# PIC32MZ1025DAH169 register map
Vendor: Microchip
Registers are 32-bit, read-write, reset 0x0 unless marked. A register's access mark holds for its fields unless they carry their own. Addresses are absolute, and some are shared; only a register's first bit layout is shown; [hi:lo] are bit positions; {n}, {i} and the like mark numbered series; 'fields as' and 'values as' point back to an identical list.

## CONFIG — Configuration words, addresses in PhysicalSpace
0x1FC0FF3C ADEVCFG4 reset 0xFFFFFFFF
  [28:24] SWDTPS — Sleep Mode Watchdog Timer Postscaler
    0=SPS1 (1:1); 1=SPS2 (1:2); 2=SPS4 (1:4); 3=SPS8 (1:8); 4=SPS16 (1:16); 5=SPS32 (1:32); 6=SPS64 (1:64); 7=SPS128 (1:128); 8=SPS256 (1:256); 9=SPS512 (1:512); 10=SPS1024 (1:1024); 11=SPS2048 (1:2048); 12=SPS4096 (1:4096); 13=SPS8192 (1:8192); 14=SPS16384 (1:16384); 15=SPS32768 (1:32768); 0b1x000=SPS65536 (1:65536); 0b1x001=SPS131072 (1:131072); 0b1x010=SPS262144 (1:262144); 0b1x011=SPS524288 (1:524288); 0b1x1xx=SPS1048576 (1:1048576)
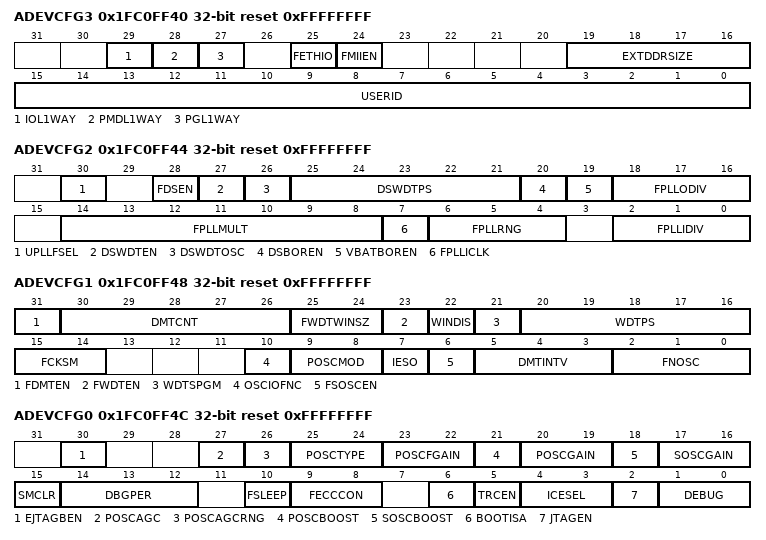
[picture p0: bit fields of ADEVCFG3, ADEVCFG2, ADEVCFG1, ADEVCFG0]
0x1FC0FF40 ADEVCFG3 reset 0xFFFFFFFF
  [29] IOL1WAY — Peripheral Pin Select Configuration
    1=ON (Allow only one reconfiguration); 0=OFF (Allow multiple reconfigurations)
  [28] PMDL1WAY — Peripheral Module Disable Configuration
    values as IOL1WAY
  [27] PGL1WAY — Permission Group Lock One Way Configuration
    values as IOL1WAY
  [25] FETHIO — Ethernet I/O Pin Select
    0=OFF (Alternate Ethernet I/O); 1=ON (Default Ethernet I/O)
  [24] FMIIEN — Ethernet RMII/MII Enable
    0=OFF (RMII Enabled); 1=ON (MII Enabled)
  [19:16] EXTDDRSIZE — External DDR2 SDRAM Memory Size
    0=DDR_SIZE_1MB (External DDR2 Size is 1 MB); 1=DDR_SIZE_2MB (External DDR2 Size is 2 MB); 2=DDR_SIZE_4MB (External DDR2 Size is 4 MB); 3=DDR_SIZE_8MB (External DDR2 Size is 8 MB); 4=DDR_SIZE_16MB (External DDR2 Size is 16 MB); 5=DDR_SIZE_32MB (External DDR2 Size is 32 MB); 6=DDR_SIZE_64MB (External DDR2 Size is 64 MB); 15=DDR_SIZE_128MB (External DDR2 Size is 128 MB)
  [15:0] USERID
0x1FC0FF44 ADEVCFG2 reset 0xFFFFFFFF
  [30] UPLLFSEL — USB PLL Input Frequency Selection
    1=FREQ_24MHZ (USB PLL input is 24 MHz); 0=FREQ_12MHZ (USB PLL input is 12 MHz)
  [28] FDSEN — Deep Sleep Enable
    0=OFF (Disable DSEN bit in DSCON); 1=ON (Enable DSEN bit in DSCON)
  [27] DSWDTEN — Deep Sleep Watchdog Timer Enable
    0=OFF (Disable DSWDT during Deep Sleep Mode); 1=ON (Enable DSWDT during Deep Sleep Mode)
  [26] DSWDTOSC — Deep Sleep WDT Reference Clock Selection
    0=SOSC (Select SOSC as DSWDT Reference Clock); 1=LPRC (Select LPRC as DSWDT Reference clock)
  [25:21] DSWDTPS — Deep Sleep Watchdog Timer Postscaler
    {v}=DSPS{v+1} (1:2^{v+5}) (v=0..31)
  [20] DSBOREN — Deep Sleep BOR Enable
    0=OFF (Disable ZPBOR during Deep Sleep Mode); 1=ON (Enable ZPBOR during Deep Sleep Mode)
  [19] VBATBOREN — VBAT BOR Enable
    0=OFF (Disable ZPBOR during VBAT Mode); 1=ON (Enable ZPBOR during VBAT Mode)
  [18:16] FPLLODIV — System PLL Output Clock Divider
    1=DIV_2 (2x Divider); 2=DIV_4 (4x Divider); 3=DIV_8 (8x Divider); 4=DIV_16 (16x Divider); 7=DIV_32 (32x Divider)
  [14:8] FPLLMULT — System PLL Multiplier
    {v}=MUL_{v+1} (PLL Multiply by {v+1}) (v=0..127)
  [7] FPLLICLK — System PLL Input Clock Selection
    1=PLL_FRC (FRC is input to the System PLL); 0=PLL_POSC (POSC is input to the System PLL)
  [6:4] FPLLRNG — System PLL Input Range
    0=RANGE_BYPASS (Bypass); 1=RANGE_5_10_MHZ (5-10 MHz Input); 2=RANGE_8_16_MHZ (8-16 MHz Input); 3=RANGE_13_26_MHZ (13-26 MHz Input); 4=RANGE_21_42_MHZ (21-42 MHz Input); 5=RANGE_34_68_MHZ (34-68 MHz Input)
  [2:0] FPLLIDIV — System PLL Input Divider
    {v}=DIV_{v+1} ({v+1}x Divider) (v=0..7)
0x1FC0FF48 ADEVCFG1 reset 0xFFFFFFFF
  [31] FDMTEN — Deadman Timer Enable
    1=ON (Deadman Timer is enabled); 0=OFF (Deadman Timer is disabled)
  [30:26] DMTCNT — Deadman Timer Count Selection
    0=DMT8 (2^8 (256)); 1=DMT9 (2^9 (512)); 2=DMT10 (2^10 (1024)); 3=DMT11 (2^11 (2048)); 4=DMT12 (2^12 (4096)); 5=DMT13 (2^13 (8192)); 6=DMT14 (2^14 (16384)); 7=DMT15 (2^15 (32768)); 8=DMT16 (2^16 (65536)); 9=DMT17 (2^17 (131072)); 10=DMT18 (2^18 (262144)); 11=DMT19 (2^19 (524288)); 12=DMT20 (2^20 (1048576)); 13=DMT21 (2^21 (2097152)); 14=DMT22 (2^22 (4194304)); 15=DMT23 (2^23 (8388608)); 16=DMT24 (2^24 (16777216)); 17=DMT25 (2^25 (33554432)); 18=DMT26 (2^26 (67108864)); 19=DMT27 (2^27 (134217728)); 20=DMT28 (2^28 (268435456)); 21=DMT29 (2^29 (536870912)); 22=DMT30 (2^30 (1073741824)); 23=DMT31 (2^31 (2147483648))
  [25:24] FWDTWINSZ — Watchdog Timer Window Size
    3=WINSZ_25 (Window size is 25%); 2=WINSZ_37 (Window size is 37.5%); 1=WINSZ_50 (Window size is 50%); 0=WINSZ_75 (Window size is 75%)
  [23] FWDTEN — Watchdog Timer Enable
    0=OFF (WDT Disabled); 1=ON (WDT Enabled)
  [22] WINDIS — Watchdog Timer Window Mode
    1=NORMAL (Watchdog Timer is in non-Window mode); 0=WINDOW (Watchdog Timer is in Window mode)
  [21] WDTSPGM — Watchdog Timer Stop During Flash Programming
    0=RUN (WDT runs during Flash programming); 1=STOP (WDT stops during Flash programming)
  [20:16] WDTPS — Watchdog Timer Postscaler
    0=PS1 (1:1); 1=PS2 (1:2); 2=PS4 (1:4); 3=PS8 (1:8); 4=PS16 (1:16); 5=PS32 (1:32); 6=PS64 (1:64); 7=PS128 (1:128); 8=PS256 (1:256); 9=PS512 (1:512); 10=PS1024 (1:1024); 11=PS2048 (1:2048); 12=PS4096 (1:4096); 13=PS8192 (1:8192); 14=PS16384 (1:16384); 15=PS32768 (1:32768); 0b1x000=PS65536 (1:65536); 0b1x001=PS131072 (1:131072); 0b1x010=PS262144 (1:262144); 0b1x011=PS524288 (1:524288); 0b1x1xx=PS1048576 (1:1048576)
  [15:14] FCKSM — Clock Switching and Monitor Selection
    0=CSDCMD (Clock Switch Disabled, FSCM Disabled); 1=CSECMD (Clock Switch Enabled, FSCM Disabled); 2=CSDCME (Clock Switch Disabled, FSCM Enabled); 3=CSECME (Clock Switch Enabled, FSCM Enabled)
  [10] OSCIOFNC — CLKO Output Signal Active on the OSCO Pin
    1=OFF (Disabled); 0=ON (Enabled)
  [9:8] POSCMOD — Primary Oscillator Configuration
    0=EC (External clock mode); 2=HS (HS osc mode); 3=OFF (Primary osc disabled)
  [7] IESO — Internal/External Switch Over
    0=OFF (Disabled); 1=ON (Enabled)
  [6] FSOSCEN — Secondary Oscillator Enable
    0=OFF (Disable Secondary Oscillator); 1=ON (Enable Secondary Oscillator)
  [5:3] DMTINTV — DMT Count Window Interval
    0=WIN_0 (Window/Interval value is zero); 1=WIN_1_2 (Window/Interval value is 1/2 counter value); 2=WIN_3_4 (Window/Interval value is 3/4 counter value); 3=WIN_7_8 (Window/Interval value is 7/8 counter value); 4=WIN_15_16 (Window/Interval value is 15/16 counter value); 5=WIN_31_32 (Window/Interval value is 31/32 counter value); 6=WIN_63_64 (Window/Interval value is 63/64 counter value); 7=WIN_127_128 (Window/Interval value is 127/128 counter value)
  [2:0] FNOSC — Oscillator Selection Bits
    7=FRCDIV (Fast RC Osc w/Div-by-N (FRCDIV)); 1=SPLL (System PLL); 2=POSC (Primary Osc (HS,EC)); 4=SOSC (Low Power Secondary Osc (SOSC)); 5=LPRC (Low Power RC Osc (LPRC))
0x1FC0FF4C ADEVCFG0 reset 0xFFFFFFFF
  [30] EJTAGBEN — EJTAG Boot Enable
    0=REDUCED (Reduced EJTAG functionality); 1=NORMAL (Normal EJTAG functionality)
  [27] POSCAGC — Primary Oscillator Auto Gain Control bit
    1=ON (POSC Auto Gain Control Enabled); 0=OFF (POSC Auto Gain Control Disabled/Manual Gain Control Enabled)
  [26] POSCAGCRNG — Primary Crystal Oscillator AGC Lock Range bit
    1=RANGE_1X; 0=RANGE_5X
  [25:24] POSCTYPE — Primary Oscillator Type bits
    3=CRYSTAL_12MHZ (12 MHz Crystal used as Primary Oscillator); 2=CRYSTAL_24MHZ (24 MHz Crystal used as Primary Oscillator); 1=RESONATOR (Resonator used as Primary Oscillator); 0=CRYSTAL_8MHZ (8 MHz Crystal used as Primary Oscillator)
  [23:22] POSCFGAIN — Primary Crystal Oscillator Final Gain Control
    {v}=GAIN_G{v} (Gain is G{v}) (v=0..3)
  [21] POSCBOOST — Primary Oscillator Boost Kick Start Enable bit
    1=ON (Boost the kick start of the oscillator); 0=OFF (Normal start of the oscillator)
  [20:19] POSCGAIN — Primary Oscillator Gain Control bits
    3=GAIN_2X (2x gain setting); 2=GAIN_1_5X (1.5x gain setting); 0=GAIN_0_5X (0.5x gain setting); 1=GAIN_1X (1x gain setting); 3=GAIN_LEVEL_3 (Gain level 3 (Highest)); 2=GAIN_LEVEL_2; 1=GAIN_LEVEL_1; 0=GAIN_LEVEL_0 (Gain level 0 (Lowest))
  [18] SOSCBOOST — Secondary Oscillator Boost Kick Start Enable bit
    values as POSCBOOST
  [17:16] SOSCGAIN — Secondary Oscillator Gain Control bits
    values as POSCGAIN
  [15] SMCLR — Soft Master Clear Enable
    0=MCLR_POR (MCLR pin generates an emulated POR Reset); 1=MCLR_NORM (MCLR pin generates a normal system Reset)
  [14:12] DBGPER — Debug Mode CPU Access Permission
    4=ALLOW_PG2 (Allow CPU access to Permission Group 2 permission regions); 2=ALLOW_PG1 (Allow CPU access to Permission Group 1 permission regions); 1=ALLOW_PG0 (Allow CPU access to Permission Group 0 permission regions); 3=PG_1_0 (PG0: Allow PG1: Allow PG2: Deny); 5=PG_2_0 (PG0: Allow PG1: Deny PG2: Allow); 6=PG_2_1 (PG0: Deny PG1: Allow PG2: Allow); 7=PG_ALL (Allow CPU access to all permission regions); 0=PG_NONE (Deny CPU access to all permission regions)
  [10] FSLEEP — Flash Sleep Mode
    0=VREGS (Flash power down is controlled by the VREGS bit); 1=OFF (Flash is powered down when the device is in Sleep mode)
  [9:8] FECCCON — Dynamic Flash ECC Configuration
    0=ON (Flash ECC is enabled (ECCCON bits are locked)); 1=DYNAMIC (Dynamic Flash ECC is enabled (ECCCON bits are locked)); 2=OFF_LOCKED (ECC and Dynamic ECC are disabled (ECCCON bits are locked)); 3=OFF_UNLOCKED (ECC and Dynamic ECC are disabled (ECCCON bits are writable))
  [6] BOOTISA — Boot ISA Selection
    1=MIPS32 (Boot code and Exception code is MIPS32); 0=MICROMIPS (Boot code and Exception code is microMIPS)
  [5] TRCEN — Trace Enable
    1=ON (Trace features in the CPU are enabled); 0=OFF (Trace features in the CPU are disabled)
  [4:3] ICESEL — ICE/ICD Comm Channel Select
    3=ICS_PGx1 (Communicate on PGEC1/PGED1); 2=ICS_PGx2 (Communicate on PGEC2/PGED2)
  [2] JTAGEN — JTAG Enable
    1=ON (JTAG Port Enabled); 0=OFF (JTAG Disabled)
  [1:0] DEBUG — Background Debugger Enable
    0=ON (Debugger is enabled); 3=OFF (Debugger is disabled)
0x1FC0FF50 ADEVCP3 access not given reset 0xFFFFFFFF
0x1FC0FF54 ADEVCP2 access not given reset 0xFFFFFFFF
0x1FC0FF58 ADEVCP1 access not given reset 0xFFFFFFFF
0x1FC0FF5C ADEVCP0 reset 0xFFFFFFFF
  [28] CP — Code Protect
    0=ON (Protection Enabled); 1=OFF (Protection Disabled)
0x1FC0FF60 ADEVSIGN3 access not given reset 0xFFFFFFFF
0x1FC0FF64 ADEVSIGN2 access not given reset 0xFFFFFFFF
0x1FC0FF68 ADEVSIGN1 access not given reset 0xFFFFFFFF
0x1FC0FF6C ADEVSIGN0 access not given reset 0x7FFFFFFF
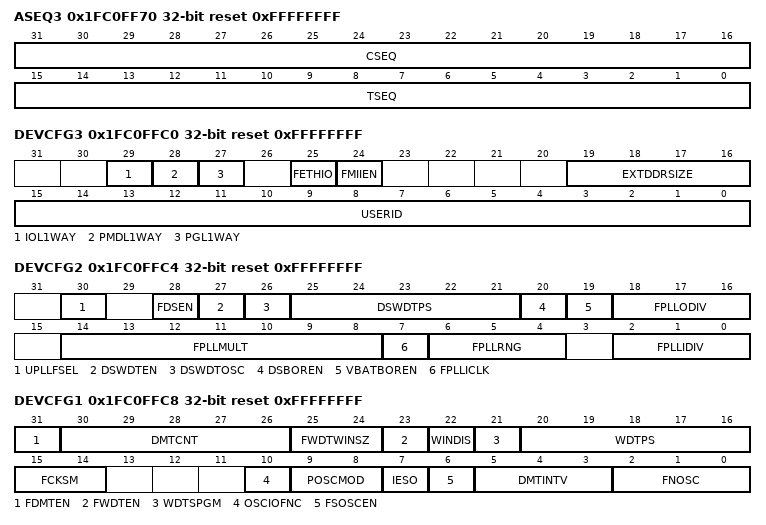
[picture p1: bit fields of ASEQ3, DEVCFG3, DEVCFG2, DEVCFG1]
0x1FC0FF70 ASEQ3 reset 0xFFFFFFFF
  [31:16] CSEQ — Boot Flash Complement Sequence Number
  [15:0] TSEQ — Boot Flash True Sequence Number
0x1FC0FF74 ASEQ2 access not given reset 0xFFFFFFFF
0x1FC0FF78 ASEQ1 access not given reset 0xFFFFFFFF
0x1FC0FF7C ASEQ0 access not given reset 0xFFFFFFFF
0x1FC0FFBC DEVCFG4 reset 0xFFFFFFFF
  fields as ADEVCFG4
0x1FC0FFC0 DEVCFG3 reset 0xFFFFFFFF
  fields as ADEVCFG3
0x1FC0FFC4 DEVCFG2 reset 0xFFFFFFFF
  fields as ADEVCFG2
0x1FC0FFC8 DEVCFG1 reset 0xFFFFFFFF
  fields as ADEVCFG1
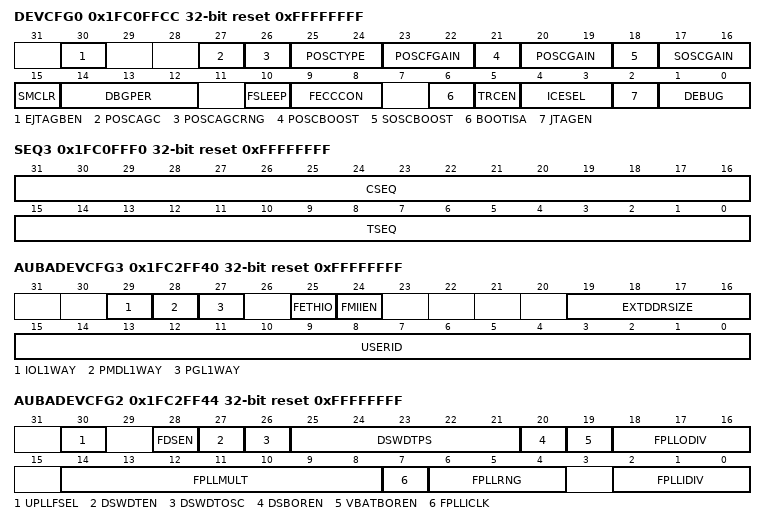
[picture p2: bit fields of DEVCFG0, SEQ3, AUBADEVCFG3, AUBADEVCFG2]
0x1FC0FFCC DEVCFG0 reset 0xFFFFFFFF
  fields as ADEVCFG0
0x1FC0FFD0 DEVCP3 access not given reset 0xFFFFFFFF
0x1FC0FFD4 DEVCP2 access not given reset 0xFFFFFFFF
0x1FC0FFD8 DEVCP1 access not given reset 0xFFFFFFFF
0x1FC0FFDC DEVCP0 reset 0xFFFFFFFF
  fields as ADEVCP0
0x1FC0FFE0 DEVSIGN3 access not given reset 0xFFFFFFFF
0x1FC0FFE4 DEVSIGN2 access not given reset 0xFFFFFFFF
0x1FC0FFE8 DEVSIGN1 access not given reset 0xFFFFFFFF
0x1FC0FFEC DEVSIGN0 access not given reset 0x7FFFFFFF
0x1FC0FFF0 SEQ3 reset 0xFFFFFFFF
  fields as ASEQ3
0x1FC0FFF4 SEQ2 access not given reset 0xFFFFFFFF
0x1FC0FFF8 SEQ1 access not given reset 0xFFFFFFFF
0x1FC0FFFC SEQ0 access not given reset 0xFFFFFFFF
0x1FC2FF3C AUBADEVCFG4 reset 0xFFFFFFFF
  fields as ADEVCFG4
0x1FC2FF40 AUBADEVCFG3 reset 0xFFFFFFFF
  fields as ADEVCFG3
0x1FC2FF44 AUBADEVCFG2 reset 0xFFFFFFFF
  fields as ADEVCFG2
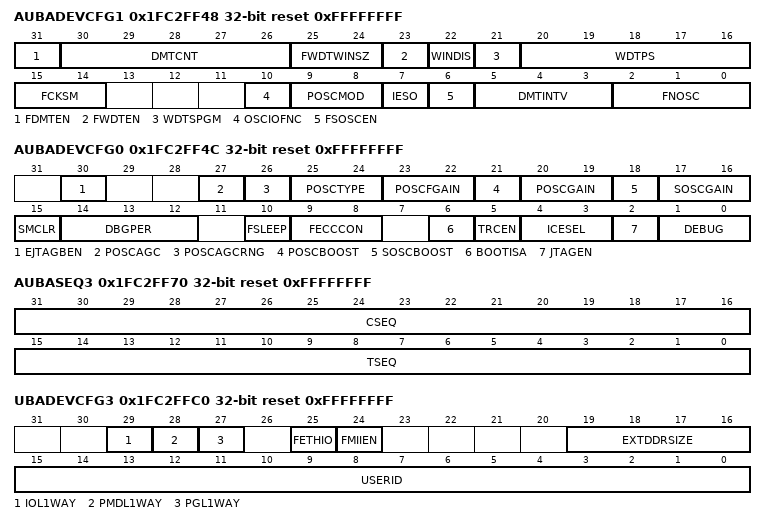
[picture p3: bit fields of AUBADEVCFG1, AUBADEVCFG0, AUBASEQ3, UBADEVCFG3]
0x1FC2FF48 AUBADEVCFG1 reset 0xFFFFFFFF
  fields as ADEVCFG1
0x1FC2FF4C AUBADEVCFG0 reset 0xFFFFFFFF
  fields as ADEVCFG0
0x1FC2FF50 AUBADEVCP3 access not given reset 0xFFFFFFFF
0x1FC2FF54 AUBADEVCP2 access not given reset 0xFFFFFFFF
0x1FC2FF58 AUBADEVCP1 access not given reset 0xFFFFFFFF
0x1FC2FF5C AUBADEVCP0 reset 0xFFFFFFFF
  fields as ADEVCP0
0x1FC2FF60 AUBADEVSIGN3 access not given reset 0xFFFFFFFF
0x1FC2FF64 AUBADEVSIGN2 access not given reset 0xFFFFFFFF
0x1FC2FF68 AUBADEVSIGN1 access not given reset 0xFFFFFFFF
0x1FC2FF6C AUBADEVSIGN0 access not given reset 0x7FFFFFFF
0x1FC2FF70 AUBASEQ3 reset 0xFFFFFFFF
  fields as ASEQ3
0x1FC2FF74 AUBASEQ2 access not given reset 0xFFFFFFFF
0x1FC2FF78 AUBASEQ1 access not given reset 0xFFFFFFFF
0x1FC2FF7C AUBASEQ0 access not given reset 0xFFFFFFFF
0x1FC2FFBC UBADEVCFG4 reset 0xFFFFFFFF
  fields as ADEVCFG4
0x1FC2FFC0 UBADEVCFG3 reset 0xFFFFFFFF
  fields as ADEVCFG3
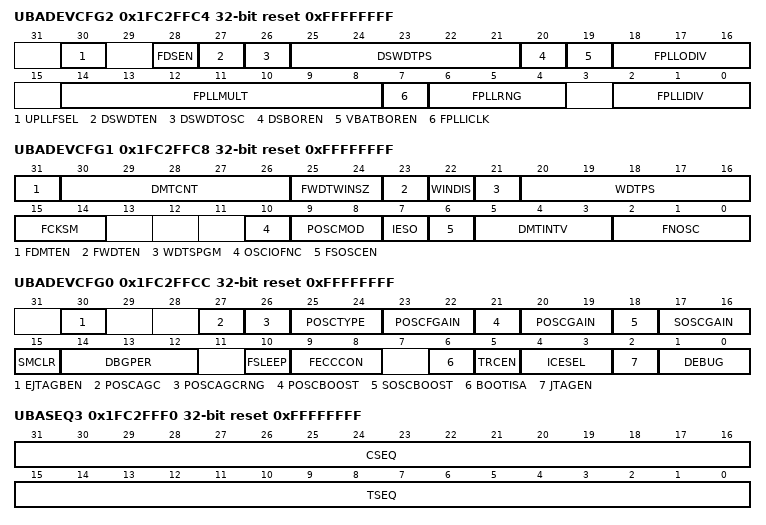
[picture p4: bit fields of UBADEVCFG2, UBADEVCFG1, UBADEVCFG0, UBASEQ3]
0x1FC2FFC4 UBADEVCFG2 reset 0xFFFFFFFF
  fields as ADEVCFG2
0x1FC2FFC8 UBADEVCFG1 reset 0xFFFFFFFF
  fields as ADEVCFG1
0x1FC2FFCC UBADEVCFG0 reset 0xFFFFFFFF
  fields as ADEVCFG0
0x1FC2FFD0 UBADEVCP3 access not given reset 0xFFFFFFFF
0x1FC2FFD4 UBADEVCP2 access not given reset 0xFFFFFFFF
0x1FC2FFD8 UBADEVCP1 access not given reset 0xFFFFFFFF
0x1FC2FFDC UBADEVCP0 reset 0xFFFFFFFF
  fields as ADEVCP0
0x1FC2FFE0 UBADEVSIGN3 access not given reset 0xFFFFFFFF
0x1FC2FFE4 UBADEVSIGN2 access not given reset 0xFFFFFFFF
0x1FC2FFE8 UBADEVSIGN1 access not given reset 0xFFFFFFFF
0x1FC2FFEC UBADEVSIGN0 access not given reset 0x7FFFFFFF
0x1FC2FFF0 UBASEQ3 reset 0xFFFFFFFF
  fields as ASEQ3
0x1FC2FFF4 UBASEQ2 access not given reset 0xFFFFFFFF
0x1FC2FFF8 UBASEQ1 access not given reset 0xFFFFFFFF
0x1FC2FFFC UBASEQ0 access not given reset 0xFFFFFFFF
0x1FC4FF3C ABF1DEVCFG4 reset 0xFFFFFFFF
  fields as ADEVCFG4
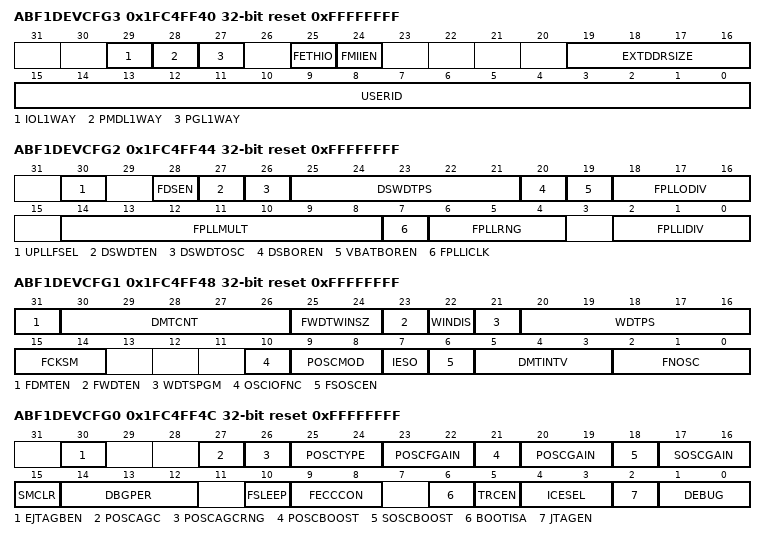
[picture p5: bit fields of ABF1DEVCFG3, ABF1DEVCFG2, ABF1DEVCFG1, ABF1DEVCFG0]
0x1FC4FF40 ABF1DEVCFG3 reset 0xFFFFFFFF
  fields as ADEVCFG3
0x1FC4FF44 ABF1DEVCFG2 reset 0xFFFFFFFF
  fields as ADEVCFG2
0x1FC4FF48 ABF1DEVCFG1 reset 0xFFFFFFFF
  fields as ADEVCFG1
0x1FC4FF4C ABF1DEVCFG0 reset 0xFFFFFFFF
  fields as ADEVCFG0
0x1FC4FF50 ABF1DEVCP3 access not given reset 0xFFFFFFFF
0x1FC4FF54 ABF1DEVCP2 access not given reset 0xFFFFFFFF
0x1FC4FF58 ABF1DEVCP1 access not given reset 0xFFFFFFFF
0x1FC4FF5C ABF1DEVCP0 reset 0xFFFFFFFF
  fields as ADEVCP0
0x1FC4FF60 ABF1DEVSIGN3 access not given reset 0xFFFFFFFF
0x1FC4FF64 ABF1DEVSIGN2 access not given reset 0xFFFFFFFF
0x1FC4FF68 ABF1DEVSIGN1 access not given reset 0xFFFFFFFF
0x1FC4FF6C ABF1DEVSIGN0 access not given reset 0x7FFFFFFF
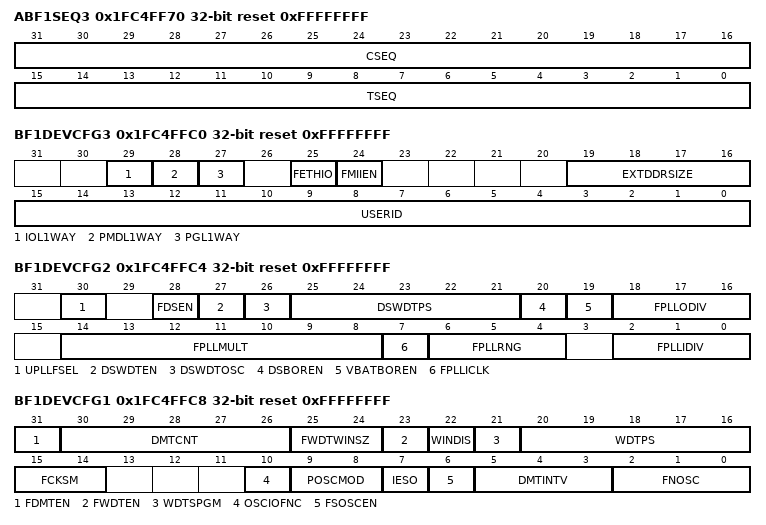
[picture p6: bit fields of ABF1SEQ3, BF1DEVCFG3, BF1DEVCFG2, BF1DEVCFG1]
0x1FC4FF70 ABF1SEQ3 reset 0xFFFFFFFF
  fields as ASEQ3
0x1FC4FF74 ABF1SEQ2 access not given reset 0xFFFFFFFF
0x1FC4FF78 ABF1SEQ1 access not given reset 0xFFFFFFFF
0x1FC4FF7C ABF1SEQ0 access not given reset 0xFFFFFFFF
0x1FC4FFBC BF1DEVCFG4 reset 0xFFFFFFFF
  fields as ADEVCFG4
0x1FC4FFC0 BF1DEVCFG3 reset 0xFFFFFFFF
  fields as ADEVCFG3
0x1FC4FFC4 BF1DEVCFG2 reset 0xFFFFFFFF
  fields as ADEVCFG2
0x1FC4FFC8 BF1DEVCFG1 reset 0xFFFFFFFF
  fields as ADEVCFG1
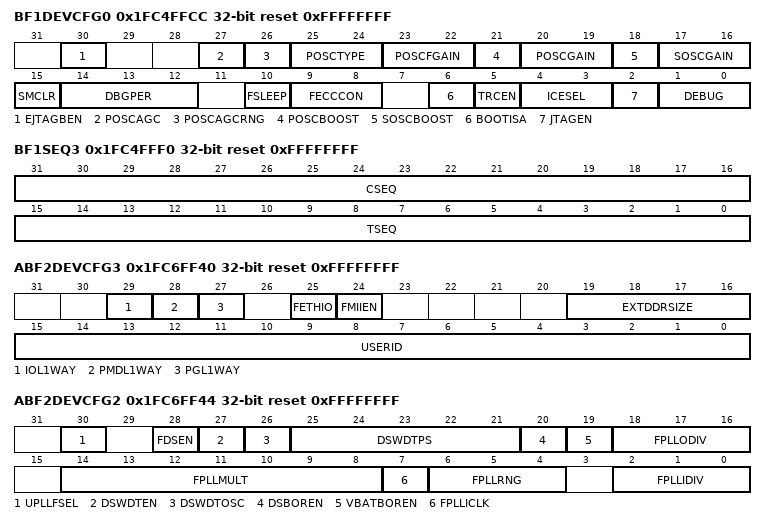
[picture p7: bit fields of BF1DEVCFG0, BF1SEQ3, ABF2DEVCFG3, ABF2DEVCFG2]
0x1FC4FFCC BF1DEVCFG0 reset 0xFFFFFFFF
  fields as ADEVCFG0
0x1FC4FFD0 BF1DEVCP3 access not given reset 0xFFFFFFFF
0x1FC4FFD4 BF1DEVCP2 access not given reset 0xFFFFFFFF
0x1FC4FFD8 BF1DEVCP1 access not given reset 0xFFFFFFFF
0x1FC4FFDC BF1DEVCP0 reset 0xFFFFFFFF
  fields as ADEVCP0
0x1FC4FFE0 BF1DEVSIGN3 access not given reset 0xFFFFFFFF
0x1FC4FFE4 BF1DEVSIGN2 access not given reset 0xFFFFFFFF
0x1FC4FFE8 BF1DEVSIGN1 access not given reset 0xFFFFFFFF
0x1FC4FFEC BF1DEVSIGN0 access not given reset 0x7FFFFFFF
0x1FC4FFF0 BF1SEQ3 reset 0xFFFFFFFF
  fields as ASEQ3
0x1FC4FFF4 BF1SEQ2 access not given reset 0xFFFFFFFF
0x1FC4FFF8 BF1SEQ1 access not given reset 0xFFFFFFFF
0x1FC4FFFC BF1SEQ0 access not given reset 0xFFFFFFFF
{0x1FC54000+4i} DEVADC{i} ro reset 0xFFFFFFFF (i=0..4)
  [31:0] ADCFG
0x1FC5401C DEVADC7 ro reset 0xFFFFFFFF
  [31:0] ADCFG
{0x1FC54020+4i} DEVSN{i} ro reset 0xFFFFFFFF (i=0..3)
  [31:0] SN
0x1FC6FF3C ABF2DEVCFG4 reset 0xFFFFFFFF
  fields as ADEVCFG4
0x1FC6FF40 ABF2DEVCFG3 reset 0xFFFFFFFF
  fields as ADEVCFG3
0x1FC6FF44 ABF2DEVCFG2 reset 0xFFFFFFFF
  fields as ADEVCFG2
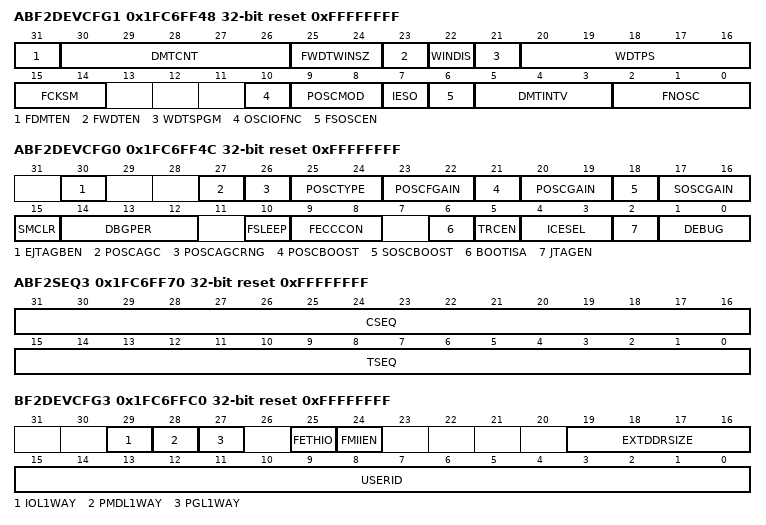
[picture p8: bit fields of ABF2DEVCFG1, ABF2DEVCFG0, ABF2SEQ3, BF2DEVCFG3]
0x1FC6FF48 ABF2DEVCFG1 reset 0xFFFFFFFF
  fields as ADEVCFG1
0x1FC6FF4C ABF2DEVCFG0 reset 0xFFFFFFFF
  fields as ADEVCFG0
0x1FC6FF50 ABF2DEVCP3 access not given reset 0xFFFFFFFF
0x1FC6FF54 ABF2DEVCP2 access not given reset 0xFFFFFFFF
0x1FC6FF58 ABF2DEVCP1 access not given reset 0xFFFFFFFF
0x1FC6FF5C ABF2DEVCP0 reset 0xFFFFFFFF
  fields as ADEVCP0
0x1FC6FF60 ABF2DEVSIGN3 access not given reset 0xFFFFFFFF
0x1FC6FF64 ABF2DEVSIGN2 access not given reset 0xFFFFFFFF
0x1FC6FF68 ABF2DEVSIGN1 access not given reset 0xFFFFFFFF
0x1FC6FF6C ABF2DEVSIGN0 access not given reset 0x7FFFFFFF
0x1FC6FF70 ABF2SEQ3 reset 0xFFFFFFFF
  fields as ASEQ3
0x1FC6FF74 ABF2SEQ2 access not given reset 0xFFFFFFFF
0x1FC6FF78 ABF2SEQ1 access not given reset 0xFFFFFFFF
0x1FC6FF7C ABF2SEQ0 access not given reset 0xFFFFFFFF
0x1FC6FFBC BF2DEVCFG4 reset 0xFFFFFFFF
  fields as ADEVCFG4
0x1FC6FFC0 BF2DEVCFG3 reset 0xFFFFFFFF
  fields as ADEVCFG3
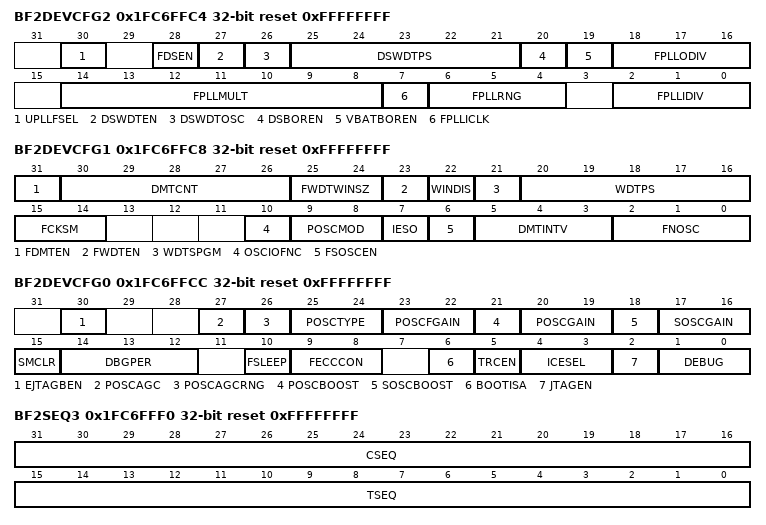
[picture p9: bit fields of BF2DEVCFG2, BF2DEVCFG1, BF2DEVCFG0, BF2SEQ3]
0x1FC6FFC4 BF2DEVCFG2 reset 0xFFFFFFFF
  fields as ADEVCFG2
0x1FC6FFC8 BF2DEVCFG1 reset 0xFFFFFFFF
  fields as ADEVCFG1
0x1FC6FFCC BF2DEVCFG0 reset 0xFFFFFFFF
  fields as ADEVCFG0
0x1FC6FFD0 BF2DEVCP3 access not given reset 0xFFFFFFFF
0x1FC6FFD4 BF2DEVCP2 access not given reset 0xFFFFFFFF
0x1FC6FFD8 BF2DEVCP1 access not given reset 0xFFFFFFFF
0x1FC6FFDC BF2DEVCP0 reset 0xFFFFFFFF
  fields as ADEVCP0
0x1FC6FFE0 BF2DEVSIGN3 access not given reset 0xFFFFFFFF
0x1FC6FFE4 BF2DEVSIGN2 access not given reset 0xFFFFFFFF
0x1FC6FFE8 BF2DEVSIGN1 access not given reset 0xFFFFFFFF
0x1FC6FFEC BF2DEVSIGN0 access not given reset 0x7FFFFFFF
0x1FC6FFF0 BF2SEQ3 reset 0xFFFFFFFF
  fields as ASEQ3
0x1FC6FFF4 BF2SEQ2 access not given reset 0xFFFFFFFF
0x1FC6FFF8 BF2SEQ1 access not given reset 0xFFFFFFFF
0x1FC6FFFC BF2SEQ0 access not given reset 0xFFFFFFFF
